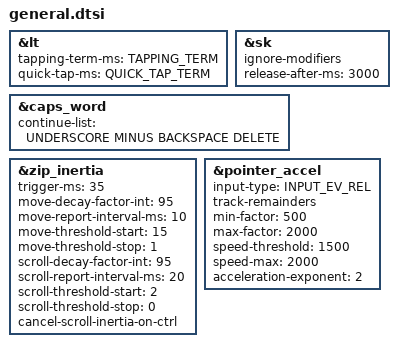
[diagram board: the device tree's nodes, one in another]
#include <behaviors.dtsi>
#include <dt-bindings/zmk/keys.h>
#include <dt-bindings/zmk/bt.h>
#include <dt-bindings/zmk/outputs.h>
#include <dt-bindings/zmk/pointing.h>
#include <dt-bindings/zmk/dynamic_macros.h>
#include <input/processors.dtsi>
#include <behaviors/input_gestures_accel.dtsi>
#include <zmk-input-inertia/input/processor/input_inertia.dtsi>

#define BASE    0 1
#define PC      0
#define MAC     1
#define GAME    2
#define GAMET   3
#define NAV     4
#define MOUSE   5
#define MEDIA   6
#define NUM     7
#define SYM     8
#define FUNC    9
#define NOTHING 10
#define STENO   11

#define TAPPING_TERM 200
#define TAPPING_TERM_RING 250
#define TAPPING_TERM_PINKY 300
#define QUICK_TAP_TERM 300

&lt {
    tapping-term-ms = <TAPPING_TERM>;
    quick-tap-ms = <QUICK_TAP_TERM>;
};

&sk {
    ignore-modifiers;
    release-after-ms = <3000>;
};

&caps_word {
  continue-list = <UNDERSCORE MINUS BACKSPACE DELETE>;
};

&zip_inertia {
    trigger-ms = <35>;

    move-decay-factor-int = <95>;
    move-report-interval-ms = <10>;
    move-threshold-start = <15>;
    move-threshold-stop = <1>;

    scroll-decay-factor-int = <95>;
    scroll-report-interval-ms = <20>;
    scroll-threshold-start = <2>;
    scroll-threshold-stop = <0>;

    cancel-scroll-inertia-on-ctrl;
};

&pointer_accel {
    input-type = <INPUT_EV_REL>;
    track-remainders;
    min-factor = <500>;
    max-factor = <2000>;
    speed-threshold = <1500>;
    speed-max = <2000>;
    acceleration-exponent = <2>;
};

